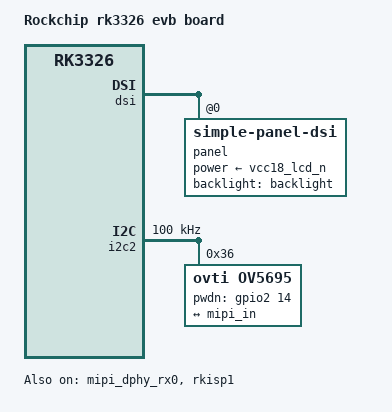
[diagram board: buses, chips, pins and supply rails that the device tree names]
// SPDX-License-Identifier: (GPL-2.0+ OR MIT)
/*
 * Copyright (c) 2021 Rockchip Electronics Co., Ltd.
 */

/dts-v1/;
#include "rk3326.dtsi"
#include "px30-android.dtsi"
#include "rk3326-evb-lp3-v10.dtsi"
#include "rk3326-863-cif-sensor.dtsi"

/ {
	model = "Rockchip rk3326 evb board";
	compatible = "rockchip,rk3326-evb-lp3-v11-avb", "rockchip,rk3326";
};

&dsi {
	status = "okay";

	panel@0 {
		compatible = "simple-panel-dsi";
		reg = <0>;
		power-supply = <&vcc18_lcd_n>;
		backlight = <&backlight>;
		prepare-delay-ms = <0>;
		reset-delay-ms = <0>;
		init-delay-ms = <80>;
		enable-delay-ms = <0>;
		disable-delay-ms = <10>;
		unprepare-delay-ms = <60>;

		width-mm = <68>;
		height-mm = <121>;

		dsi,flags = <(MIPI_DSI_MODE_VIDEO | MIPI_DSI_MODE_VIDEO_BURST |
			      MIPI_DSI_MODE_LPM | MIPI_DSI_MODE_EOT_PACKET)>;
		dsi,format = <MIPI_DSI_FMT_RGB888>;
		dsi,lanes = <4>;

		panel-init-sequence = [
			39 00 04 ff 98 81 03
			15 00 02 01 00
			15 00 02 02 00
			15 00 02 03 53
			15 00 02 04 53
			15 00 02 05 13
			15 00 02 06 04
			15 00 02 07 02
			15 00 02 08 02
			15 00 02 09 00
			15 00 02 0a 00
			15 00 02 0b 00
			15 00 02 0c 00
			15 00 02 0d 00
			15 00 02 0e 00
			15 00 02 0f 00

			15 00 02 10 00
			15 00 02 11 00
			15 00 02 12 00
			15 00 02 13 00
			15 00 02 14 00
			15 00 02 15 08
			15 00 02 16 10
			15 00 02 17 00
			15 00 02 18 08
			15 00 02 19 00
			15 00 02 1a 00
			15 00 02 1b 00
			15 00 02 1c 00
			15 00 02 1d 00
			15 00 02 1e c0
			15 00 02 1f 80

			15 00 02 20 02
			15 00 02 21 09
			15 00 02 22 00
			15 00 02 23 00
			15 00 02 24 00
			15 00 02 25 00
			15 00 02 26 00
			15 00 02 27 00
			15 00 02 28 55
			15 00 02 29 03
			15 00 02 2a 00
			15 00 02 2b 00
			15 00 02 2c 00
			15 00 02 2d 00
			15 00 02 2e 00
			15 00 02 2f 00

			15 00 02 30 00
			15 00 02 31 00
			15 00 02 32 00
			15 00 02 33 00
			15 00 02 34 04
			15 00 02 35 05
			15 00 02 36 05
			15 00 02 37 00
			15 00 02 38 3c
			15 00 02 39 35
			15 00 02 3a 00
			15 00 02 3b 40
			15 00 02 3c 00
			15 00 02 3d 00
			15 00 02 3e 00
			15 00 02 3f 00

			15 00 02 40 00
			15 00 02 41 88
			15 00 02 42 00
			15 00 02 43 00
			15 00 02 44 1f

			15 00 02 50 01
			15 00 02 51 23
			15 00 02 52 45
			15 00 02 53 67
			15 00 02 54 89
			15 00 02 55 ab
			15 00 02 56 01
			15 00 02 57 23
			15 00 02 58 45
			15 00 02 59 67
			15 00 02 5a 89
			15 00 02 5b ab
			15 00 02 5c cd
			15 00 02 5d ef
			15 00 02 5e 03
			15 00 02 5f 14

			15 00 02 60 15
			15 00 02 61 0c
			15 00 02 62 0d
			15 00 02 63 0e
			15 00 02 64 0f
			15 00 02 65 10
			15 00 02 66 11
			15 00 02 67 08
			15 00 02 68 02
			15 00 02 69 0a
			15 00 02 6a 02
			15 00 02 6b 02
			15 00 02 6c 02
			15 00 02 6d 02
			15 00 02 6e 02
			15 00 02 6f 02

			15 00 02 70 02
			15 00 02 71 02
			15 00 02 72 06
			15 00 02 73 02
			15 00 02 74 02
			15 00 02 75 14
			15 00 02 76 15
			15 00 02 77 0f
			15 00 02 78 0e
			15 00 02 79 0d
			15 00 02 7a 0c
			15 00 02 7b 11
			15 00 02 7c 10
			15 00 02 7d 06
			15 00 02 7e 02
			15 00 02 7f 0a

			15 00 02 80 02
			15 00 02 81 02
			15 00 02 82 02
			15 00 02 83 02
			15 00 02 84 02
			15 00 02 85 02
			15 00 02 86 02
			15 00 02 87 02
			15 00 02 88 08
			15 00 02 89 02
			15 00 02 8a 02

			39 00 04 ff 98 81 04
			15 00 02 00 80
			15 00 02 70 00
			15 00 02 71 00
			15 00 02 66 fe
			15 00 02 82 15
			15 00 02 84 15
			15 00 02 85 15
			15 00 02 3a 24
			15 00 02 32 ac
			15 00 02 8c 80
			15 00 02 3c f5
			15 00 02 88 33

			39 00 04 ff 98 81 01
			15 00 02 22 0a
			15 00 02 31 00
			15 00 02 53 78
			15 00 02 50 5b
			15 00 02 51 5b
			15 00 02 60 20
			15 00 02 61 00
			15 00 02 62 0d
			15 00 02 63 00

			15 00 02 a0 00
			15 00 02 a1 10
			15 00 02 a2 1c
			15 00 02 a3 13
			15 00 02 a4 15
			15 00 02 a5 26
			15 00 02 a6 1a
			15 00 02 a7 1d
			15 00 02 a8 67
			15 00 02 a9 1c
			15 00 02 aa 29
			15 00 02 ab 5b
			15 00 02 ac 26
			15 00 02 ad 28
			15 00 02 ae 5c
			15 00 02 af 30
			15 00 02 b0 31
			15 00 02 b1 2e
			15 00 02 b2 32
			15 00 02 b3 00

			15 00 02 c0 00
			15 00 02 c1 10
			15 00 02 c2 1c
			15 00 02 c3 13
			15 00 02 c4 15
			15 00 02 c5 26
			15 00 02 c6 1a
			15 00 02 c7 1d
			15 00 02 c8 67
			15 00 02 c9 1c
			15 00 02 ca 29
			15 00 02 cb 5b
			15 00 02 cc 26
			15 00 02 cd 28
			15 00 02 ce 5c
			15 00 02 cf 30
			15 00 02 d0 31
			15 00 02 d1 2e
			15 00 02 d2 32
			15 00 02 d3 00
			39 00 04 ff 98 81 00
			05 00 01 11
			05 01 01 29
		];

		panel-exit-sequence = [
			05 00 01 28
			05 00 01 10
		];

		display-timings {
			native-mode = <&timing1>;

			timing1: timing1 {
				clock-frequency = <64000000>;
				hactive = <720>;
				vactive = <1280>;
				hfront-porch = <40>;
				hsync-len = <10>;
				hback-porch = <40>;
				vfront-porch = <22>;
				vsync-len = <4>;
				vback-porch = <11>;
				hsync-active = <0>;
				vsync-active = <0>;
				de-active = <0>;
				pixelclk-active = <0>;
			};
		};
	};

};

&i2c2 {
	status = "okay";

	clock-frequency = <100000>;

	/* These are relatively safe rise/fall times; TODO: measure */
	i2c-scl-falling-time-ns = <50>;
	i2c-scl-rising-time-ns = <300>;

	ov5695: ov5695@36 {
		compatible = "ovti,ov5695";
		reg = <0x36>;
		clocks = <&cru SCLK_CIF_OUT>;
		clock-names = "xvclk";
		/*reset-gpios = <&gpio2 14 GPIO_ACTIVE_HIGH>;*/
		pwdn-gpios = <&gpio2 14 GPIO_ACTIVE_HIGH>;
		//pinctrl-names = "default";
		//pinctrl-0 = <&cif_clkout_m0>;
		rockchip,camera-module-index = <0>;
		rockchip,camera-module-facing = "back";
		rockchip,camera-module-name = "TongJu";
		rockchip,camera-module-lens-name = "CHT842-MD";
		port {
			ov5695_out: endpoint {
				remote-endpoint = <&mipi_in>;
				data-lanes = <1 2>;
			};
		};
	};
};

&mipi_dphy_rx0 {
	status = "okay";

	ports {
		#address-cells = <1>;
		#size-cells = <0>;

		port@0 {
			reg = <0>;
			#address-cells = <1>;
			#size-cells = <0>;

			mipi_in: endpoint@1 {
				reg = <1>;
				remote-endpoint = <&ov5695_out>;
				data-lanes = <1 2>;
			};
		};

		port@1 {
			reg = <1>;
			#address-cells = <1>;
			#size-cells = <0>;

			dphy_rx_out: endpoint@0 {
				reg = <0>;
				remote-endpoint = <&isp_mipi_in>;
			};
		};
	};
};

&rkisp1 {
	status = "okay";
	pinctrl-names = "default";
	pinctrl-0 = <&cif_clkout_m0 &dvp_d0d1_m0 &dvp_d2d9_m0>;
	port {
		#address-cells = <1>;
		#size-cells = <0>;

		isp_mipi_in: endpoint@0 {
			reg = <0>;
			remote-endpoint = <&dphy_rx_out>;
		};

	};
};
